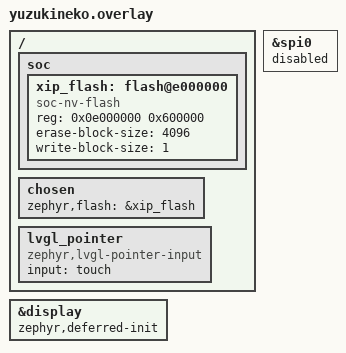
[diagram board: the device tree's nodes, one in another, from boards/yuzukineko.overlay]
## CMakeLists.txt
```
# SPDX-License-Identifier: Apache-2.0

cmake_minimum_required(VERSION 3.20.0)
# the emulator modules sit next to this application
list(APPEND ZEPHYR_EXTRA_MODULES ${CMAKE_CURRENT_SOURCE_DIR}/../mgba ${CMAKE_CURRENT_SOURCE_DIR}/../gbsp ${CMAKE_CURRENT_SOURCE_DIR}/../nes
	${CMAKE_CURRENT_SOURCE_DIR}/../aic8800 ${CMAKE_CURRENT_SOURCE_DIR}/../dlna
	${CMAKE_CURRENT_SOURCE_DIR}/../miracast)

find_package(Zephyr REQUIRED HINTS $ENV{ZEPHYR_BASE})
project(nekobox)

# sources include each other as "core/cfg.h"; LVGL includes lv_rvv.h from its blend sources
zephyr_include_directories(src src/gfx)

# the start steps and the registries of the user interface are read only records that the
# modules register; the linker collects them
zephyr_linker_sources(SECTIONS src/core/sections-rom.ld)
zephyr_linker_sources(SECTIONS src/ui/sections-rom.ld)

target_sources(app PRIVATE src/main.c)
add_subdirectory(src/core)
add_subdirectory(src/ui)
add_subdirectory(src/gfx)
add_subdirectory(src/debug)
add_subdirectory(src/features/home)
add_subdirectory(src/features/files)
add_subdirectory(src/features/settings)
add_subdirectory(src/features/video)
add_subdirectory(src/features/photos)
add_subdirectory(src/features/calculator)
add_subdirectory(src/features/games)
add_subdirectory(src/features/usbdisplay)
add_subdirectory(src/features/net)
add_subdirectory(src/features/dlna)
add_subdirectory(src/features/miracast)
```

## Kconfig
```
# SPDX-License-Identifier: Apache-2.0

mainmenu "NekoBox"

rsource "src/core/Kconfig"
rsource "src/gfx/Kconfig"
rsource "src/features/*/Kconfig"
rsource "src/debug/Kconfig"

source "Kconfig.zephyr"
```

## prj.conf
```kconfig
# the whole image runs from the flash window of the SPIF controller (see boards/yuzukineko.overlay)
CONFIG_XIP=y

CONFIG_SDHC=y
CONFIG_DISK_ACCESS=y
CONFIG_DISK_DRIVER_SDMMC=y
CONFIG_FILE_SYSTEM=y
CONFIG_FAT_FILESYSTEM_ELM=y
CONFIG_FS_FATFS_EXFAT=y
CONFIG_FS_FATFS_LFN=y
CONFIG_FS_FATFS_LFN_MODE_STACK=y
# the audio and the video thread read the same card, and the file browser does too
CONFIG_FS_FATFS_REENTRANT=y
CONFIG_LOG=y
CONFIG_LOG_PRINTK=n
CONFIG_PRINTK=y
CONFIG_SHELL=n
CONFIG_DEVMEM_SHELL=n
CONFIG_MAIN_STACK_SIZE=16384
# the malloc arena is all the RAM above the image: the buffers of the decoders, the display and
# the memory of a game (gpSP) come out of it
CONFIG_COMMON_LIBC_MALLOC_ARENA_SIZE=-1
CONFIG_HEAP_MEM_POOL_SIZE=196608
CONFIG_MAIN_THREAD_PRIORITY=8

# drivers the player does not use
CONFIG_G2D=n
CONFIG_ADC=n
CONFIG_SPI=n
CONFIG_MIPI_DBI=n
CONFIG_WDT_SUNXI=n
CONFIG_GPIO=y
CONFIG_FPU=y
CONFIG_FPU_SHARING=y

# the user interface: LVGL on the ARGB frame buffer plane, over the video plane
CONFIG_DISPLAY=y
CONFIG_DISPLAY_SUNXI_ARGB8888=y
CONFIG_LVGL=y
CONFIG_LV_COLOR_DEPTH_32=y
CONFIG_LV_Z_MEM_POOL_SIZE=262144
CONFIG_LV_Z_VDB_SIZE=15
CONFIG_LV_Z_SHELL=n
CONFIG_LV_USE_LABEL=y
CONFIG_LV_USE_BUTTON=y
CONFIG_LV_USE_SLIDER=y
CONFIG_LV_USE_ROLLER=y
CONFIG_LV_USE_LIST=y
CONFIG_LV_USE_IMAGE=y
CONFIG_LV_FONT_MONTSERRAT_14=y
CONFIG_LV_FONT_MONTSERRAT_16=y
CONFIG_LV_FONT_MONTSERRAT_20=y
CONFIG_LV_FONT_MONTSERRAT_24=y
CONFIG_LV_FONT_MONTSERRAT_28=y
CONFIG_LV_FONT_MONTSERRAT_48=y

# the touch events are handled above the thread of the user interface: a long redraw of the main
# thread must not make the input queue overflow
CONFIG_INPUT_THREAD_PRIORITY_OVERRIDE=y
CONFIG_INPUT_THREAD_PRIORITY=2
CONFIG_INPUT_QUEUE_MAX_MSGS=64
CONFIG_LV_Z_POINTER_INPUT_MSGQ_COUNT=32

# -Og is the default; the drawing code of LVGL and the decoders need the speed
CONFIG_SPEED_OPTIMIZATIONS=y

# the vector blends (src/gfx/lv_rvv.c) are included into the LVGL sources
CONFIG_LV_DRAW_SW_ASM_CUSTOM=y
CONFIG_LV_DRAW_SW_ASM_CUSTOM_INCLUDE="lv_rvv.h"

# the real time clock
CONFIG_RTC=y

CONFIG_NET_IPV6=n
CONFIG_LV_USE_SWITCH=y
CONFIG_LV_USE_KEYBOARD=y
CONFIG_LV_USE_TEXTAREA=y
CONFIG_THREAD_NAME=y
CONFIG_LV_Z_AUTO_INIT=n

# a card with no file system that can be read is never formatted by the player
CONFIG_FS_FATFS_MKFS=n
CONFIG_FS_FATFS_MOUNT_MKFS=n

# gpSP has C++ sources
CONFIG_CPP=y
CONFIG_STD_CPP17=y

# gpSP keeps this much of a GBA ROM in memory (the rest is read from the card in pages); the 8 MiB
# arena also holds its translation caches and the pictures. mGBA only plays the small Game Boy ROMs.
CONFIG_GBSP_ROM_BUFFER_MB=5
CONFIG_MGBA_MAX_ROM_SIZE_MB=6

# one decoder takes at most this much of the malloc arena for its pictures: the rest (about 3 MB)
# is for the Wi-Fi check at the start, the audio decoder and the other threads
CONFIG_VDEC_SUNXI_MAX_MEMORY_KB=8192
```

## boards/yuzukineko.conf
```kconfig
# the touch panel: the controller is on I2C, the input thread runs above the UI and the player
CONFIG_I2C=y
CONFIG_INPUT=y
CONFIG_INPUT_GT967_MAX_TOUCH_POINTS=2
```

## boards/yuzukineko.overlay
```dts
/*
 * NEKOBOX runs in place from the flash: the image is linked into the memory window of the SPIF
 * controller, which the boot stub (SyterKit xip-boot) maps from the flash offset 0x8000 at
 * 0x0e000000. The window is 6 MiB, up to the end of the 16 MiB flash.
 */

/ {
	soc {
		xip_flash: flash@e000000 {
			compatible = "soc-nv-flash";
			reg = <0x0e000000 0x600000>;
			erase-block-size = <4096>;
			write-block-size = <1>;
		};
	};

	chosen {
		zephyr,flash = &xip_flash;
	};

	/* LVGL reads the GT967 touch panel as a pointer */
	lvgl_pointer {
		compatible = "zephyr,lvgl-pointer-input";
		input = <&touch>;
	};
};

/* spi0 uses the pins of the flash (PC0..PC5): switching them away would cut the window off */
&spi0 {
	status = "disabled";
};

/* the panel is brought up by the application in a thread of its own, in parallel with the rest of the start */
&display {
	zephyr,deferred-init;
};
```

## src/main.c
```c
/*
 * Copyright (c) 2026 Yuzuki Tsuru
 *
 * SPDX-License-Identifier: Apache-2.0
 */

/*
 * NEKOBOX: a small media player for the YuzukiNeko. A home screen with a clock leads to the video
 * player, the file browser, the photo viewer and the USB second screen. The user interface is
 * LVGL on the ARGB frame buffer plane; the video, the photos and the second screen go to the
 * video plane underneath. The whole image runs in place from the flash (XIP).
 *
 * main() only runs the start stages; what happens in them is registered by the modules with
 * NEKOBOX_INIT (core/app.h).
 */

#include <zephyr/kernel.h>
#include <zephyr/sys/printk.h>

#include "core/app.h"
#include "ui/ui.h"

int main(void)
{
	static const enum nekobox_stage stages[] = {
		NEKOBOX_STAGE_EARLY, NEKOBOX_STAGE_STORAGE, NEKOBOX_STAGE_UI, NEKOBOX_STAGE_SERVICES,
	};

	printk("nekobox: boot %u ms: main starts\n", k_uptime_get_32());
	for (int i = 0; i < ARRAY_SIZE(stages); i++) {
		if (nekobox_run_stage(stages[i]) != 0) {
			printk("nekobox: start failed in stage %d\n", stages[i]);
			return 0;
		}
	}
	ui_present();
	nekobox_run_stage(NEKOBOX_STAGE_READY);
	ui_loop();

	return 0;
}
```
